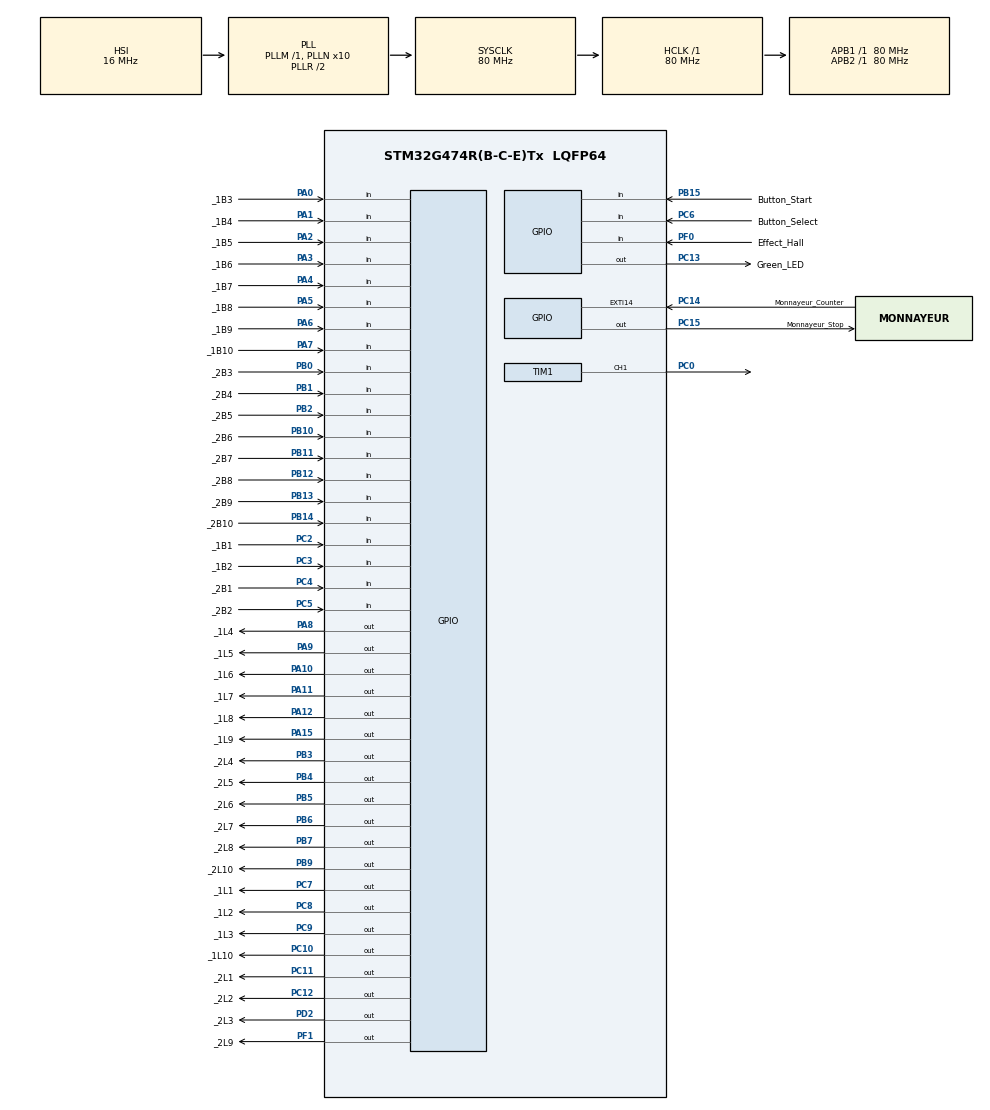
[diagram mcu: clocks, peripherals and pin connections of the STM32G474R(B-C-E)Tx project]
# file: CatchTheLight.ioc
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Dma.Request0=TIM1_CH1
Dma.TIM1_CH1.0.Direction=DMA_MEMORY_TO_PERIPH
Dma.TIM1_CH1.0.EventEnable=DISABLE
Dma.TIM1_CH1.0.Instance=DMA1_Channel1
Dma.TIM1_CH1.0.MemDataAlignment=DMA_MDATAALIGN_HALFWORD
Dma.TIM1_CH1.0.MemInc=DMA_MINC_ENABLE
Dma.TIM1_CH1.0.Mode=DMA_NORMAL
Dma.TIM1_CH1.0.PeriphDataAlignment=DMA_PDATAALIGN_HALFWORD
Dma.TIM1_CH1.0.PeriphInc=DMA_PINC_DISABLE
Dma.TIM1_CH1.0.Polarity=HAL_DMAMUX_REQ_GEN_RISING
Dma.TIM1_CH1.0.Priority=DMA_PRIORITY_MEDIUM
Dma.TIM1_CH1.0.RequestNumber=1
Dma.TIM1_CH1.0.SignalID=NONE
Dma.TIM1_CH1.0.SyncEnable=DISABLE
Dma.TIM1_CH1.0.SyncPolarity=HAL_DMAMUX_SYNC_NO_EVENT
Dma.TIM1_CH1.0.SyncRequestNumber=1
Dma.TIM1_CH1.0.SyncSignalID=NONE
Mcu.Family=STM32G4
Mcu.Name=STM32G474R(B-C-E)Tx
Mcu.Package=LQFP64
NVIC.DMA1_Channel1_IRQn=true\:0\:0\:false\:false\:true\:false\:true\:true
NVIC.PriorityGroup=NVIC_PRIORITYGROUP_4
PA0.GPIO_Label=_1B3
PA0.Signal=GPIO_Input
PA1.GPIO_Label=_1B4
PA1.Signal=GPIO_Input
PA10.GPIO_Label=_1L6
PA10.Signal=GPIO_Output
PA11.GPIO_Label=_1L7
PA11.Signal=GPIO_Output
PA12.GPIO_Label=_1L8
PA12.Signal=GPIO_Output
PA13.Mode=Serial_Wire
PA13.Signal=SYS_JTMS-SWDIO
PA14.Mode=Serial_Wire
PA14.Signal=SYS_JTCK-SWCLK
PA15.GPIO_Label=_1L9
PA15.Signal=GPIO_Output
PA2.GPIO_Label=_1B5
PA2.Signal=GPIO_Input
PA3.GPIO_Label=_1B6
PA3.Signal=GPIO_Input
PA4.GPIO_Label=_1B7
PA4.Signal=GPIO_Input
PA5.GPIO_Label=_1B8
PA5.Signal=GPIO_Input
PA6.GPIO_Label=_1B9
PA6.Signal=GPIO_Input
PA7.GPIO_Label=_1B10
PA7.Signal=GPIO_Input
PA8.GPIO_Label=_1L4
PA8.Signal=GPIO_Output
PA9.GPIO_Label=_1L5
PA9.Signal=GPIO_Output
PB0.GPIO_Label=_2B3
PB0.Signal=GPIO_Input
PB1.GPIO_Label=_2B4
PB1.Signal=GPIO_Input
PB10.GPIO_Label=_2B6
PB10.Signal=GPIO_Input
PB11.GPIO_Label=_2B7
PB11.Signal=GPIO_Input
PB12.GPIO_Label=_2B8
PB12.Signal=GPIO_Input
PB13.GPIO_Label=_2B9
PB13.Signal=GPIO_Input
PB14.GPIO_Label=_2B10
PB14.Signal=GPIO_Input
PB15.GPIO_Label=Button_Start
PB15.Signal=GPIO_Input
PB2.GPIO_Label=_2B5
PB2.Signal=GPIO_Input
PB3.GPIO_Label=_2L4
PB3.Signal=GPIO_Output
PB4.GPIO_Label=_2L5
PB4.Signal=GPIO_Output
PB5.GPIO_Label=_2L6
PB5.Signal=GPIO_Output
PB6.GPIO_Label=_2L7
PB6.Signal=GPIO_Output
PB7.GPIO_Label=_2L8
PB7.Signal=GPIO_Output
PB9.GPIO_Label=_2L10
PB9.Signal=GPIO_Output
PC0.Signal=S_TIM1_CH1
PC10.GPIO_Label=_1L10
PC10.Signal=GPIO_Output
PC11.GPIO_Label=_2L1
PC11.Signal=GPIO_Output
PC12.GPIO_Label=_2L2
PC12.Signal=GPIO_Output
PC13.GPIO_Label=Green_LED
PC13.Signal=GPIO_Output
PC14-OSC32_IN.GPIO_Label=Monnayeur_Counter
PC14-OSC32_IN.Signal=GPXTI14
PC15-OSC32_OUT.GPIO_Label=Monnayeur_Stop
PC15-OSC32_OUT.Signal=GPIO_Output
PC2.GPIO_Label=_1B1
PC2.Signal=GPIO_Input
PC3.GPIO_Label=_1B2
PC3.Signal=GPIO_Input
PC4.GPIO_Label=_2B1
PC4.Signal=GPIO_Input
PC5.GPIO_Label=_2B2
PC5.Signal=GPIO_Input
PC6.GPIO_Label=Button_Select
PC6.Signal=GPIO_Input
PC7.GPIO_Label=_1L1
PC7.Signal=GPIO_Output
PC8.GPIO_Label=_1L2
PC8.Signal=GPIO_Output
PC9.GPIO_Label=_1L3
PC9.Signal=GPIO_Output
PD2.GPIO_Label=_2L3
PD2.Signal=GPIO_Output
PF0-OSC_IN.GPIO_Label=Effect_Hall
PF0-OSC_IN.Signal=GPIO_Input
PF1-OSC_OUT.GPIO_Label=_2L9
PF1-OSC_OUT.Signal=GPIO_Output
ProjectManager.HeapSize=0x200
ProjectManager.StackSize=0x400
ProjectManager.TargetToolchain=STM32CubeIDE
RCC.ADC12Freq_Value=80000000
RCC.ADC345Freq_Value=80000000
RCC.AHBFreq_Value=80000000
RCC.APB1Freq_Value=80000000
RCC.APB1TimFreq_Value=80000000
RCC.APB2Freq_Value=80000000
RCC.APB2TimFreq_Value=80000000
RCC.CortexFreq_Value=80000000
RCC.EXTERNAL_CLOCK_VALUE=12288000
RCC.HCLKFreq_Value=80000000
RCC.HSE_VALUE=8000000
RCC.HSI48_VALUE=48000000
RCC.HSI_VALUE=16000000
RCC.LSE_VALUE=32768
RCC.PLLN=10
RCC.SYSCLKFreq_VALUE=80000000
RCC.SYSCLKSource=RCC_SYSCLKSOURCE_PLLCLK
RCC.USBFreq_Value=80000000
RCC.VCOOutputFreq_Value=160000000
SH.S_TIM1_CH1.0=TIM1_CH1,PWM Generation1 CH1
TIM1.Channel-PWM\ Generation1\ CH1=TIM_CHANNEL_1
TIM1.PeriodNoDither=79
VP_SYS_VS_DBSignals.Mode=DisableDeadBatterySignals
VP_TIM1_VS_ClockSourceINT.Mode=Internal
board=custom

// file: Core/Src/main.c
/* USER CODE BEGIN Header */
/**
 ******************************************************************************
 * @file           : main.c
 * @brief          : Main program body
 ******************************************************************************
 * @attention
 *
 * Copyright (c) 2026 STMicroelectronics.
 * All rights reserved.
 *
 * This software is licensed under terms that can be found in the LICENSE file
 * in the root directory of this software component.
 * If no LICENSE file comes with this software, it is provided AS-IS.
 *
 ******************************************************************************
 */
/* USER CODE END Header */
#include "main.h"

/* USER CODE BEGIN Includes */
#include "utils.h"
/* USER CODE END Includes */

TIM_HandleTypeDef htim1;
DMA_HandleTypeDef hdma_tim1_ch1;

void SystemClock_Config(void);
static void MX_GPIO_Init(void);
static void MX_DMA_Init(void);
static void MX_TIM1_Init(void);

int main(void)
{

	/* MCU Configuration--------------------------------------------------------*/

	/* Reset of all peripherals, Initializes the Flash interface and the Systick. */
	HAL_Init();

	/* Configure the system clock */
	SystemClock_Config();

	/* Initialize all configured peripherals */
	MX_GPIO_Init();
	MX_DMA_Init();
	MX_TIM1_Init();
	/* USER CODE BEGIN 2 */

	SETUP();
	//setup();

	/* USER CODE END 2 */

	/* Infinite loop */
	while (1)
	{

		/* USER CODE BEGIN 3 */
		//		HAL_GPIO_WritePin(GPIOB,GPIO_PIN_9,SET);
		//		HAL_Delay(1000);
		//		if (HAL_GPIO_ReadPin(GPIOC,GPIO_PIN_2)==0)
		//		{
		//			HAL_GPIO_WritePin(GPIOC,GPIO_PIN_13,1);
		//		}
		//		HAL_GPIO_WritePin(GPIOC,GPIO_PIN_13,0);
		//		HAL_Delay(1000);
		//		HAL_GPIO_WritePin(GPIOF,GPIO_PIN_1,SET);
		//test_led();
		//blinking_all();
		//if (HAL_GPIO_ReadPin(GPIOB,GPIO_PIN_15)==0){EteindreAll();}
		//EteindreAll();
		//=================================================================
		LOOP();
		//chenillard2();
		//inv_chenillard2();
		//test();
		//loop();
//		zero(1,'b');
//		HAL_Delay(1000);
//		un(1,'b');
//		HAL_Delay(1000);
//		deux(1,'b');
//		HAL_Delay(1000);
//		trois(1,'b');
//		HAL_Delay(1000);
//		quatre(1,'b');
//		HAL_Delay(1000);
//		cinq(1,'b');
//		HAL_Delay(1000);
//		six(1,'b');
//		HAL_Delay(1000);
//		sept(1,'b');
//		HAL_Delay(1000);
//		huit(1,'b');
//		HAL_Delay(1000);
//		neuf(1,'b');
//		HAL_Delay(1000);

	}
	/* USER CODE END 3 */
}

void SystemClock_Config(void)
{
	RCC_OscInitTypeDef RCC_OscInitStruct = {0};
	RCC_ClkInitTypeDef RCC_ClkInitStruct = {0};

	/** Configure the main internal regulator output voltage
	 */
	HAL_PWREx_ControlVoltageScaling(PWR_REGULATOR_VOLTAGE_SCALE1);

	/** Initializes the RCC Oscillators according to the specified parameters
	 * in the RCC_OscInitTypeDef structure.
	 */
	RCC_OscInitStruct.OscillatorType = RCC_OSCILLATORTYPE_HSI;
	RCC_OscInitStruct.HSIState = RCC_HSI_ON;
	RCC_OscInitStruct.HSICalibrationValue = RCC_HSICALIBRATION_DEFAULT;
	RCC_OscInitStruct.PLL.PLLState = RCC_PLL_ON;
	RCC_OscInitStruct.PLL.PLLSource = RCC_PLLSOURCE_HSI;
	RCC_OscInitStruct.PLL.PLLM = RCC_PLLM_DIV1;
	RCC_OscInitStruct.PLL.PLLN = 10;
	RCC_OscInitStruct.PLL.PLLP = RCC_PLLP_DIV2;
	RCC_OscInitStruct.PLL.PLLQ = RCC_PLLQ_DIV2;
	RCC_OscInitStruct.PLL.PLLR = RCC_PLLR_DIV2;
	if (HAL_RCC_OscConfig(&RCC_OscInitStruct) != HAL_OK)
	{
		Error_Handler();
	}

	/** Initializes the CPU, AHB and APB buses clocks
	 */
	RCC_ClkInitStruct.ClockType = RCC_CLOCKTYPE_HCLK|RCC_CLOCKTYPE_SYSCLK
			|RCC_CLOCKTYPE_PCLK1|RCC_CLOCKTYPE_PCLK2;
	RCC_ClkInitStruct.SYSCLKSource = RCC_SYSCLKSOURCE_PLLCLK;
	RCC_ClkInitStruct.AHBCLKDivider = RCC_SYSCLK_DIV1;
	RCC_ClkInitStruct.APB1CLKDivider = RCC_HCLK_DIV1;
	RCC_ClkInitStruct.APB2CLKDivider = RCC_HCLK_DIV1;

	if (HAL_RCC_ClockConfig(&RCC_ClkInitStruct, FLASH_LATENCY_2) != HAL_OK)
	{
		Error_Handler();
	}
}

static void MX_TIM1_Init(void)
{

	TIM_ClockConfigTypeDef sClockSourceConfig = {0};
	TIM_MasterConfigTypeDef sMasterConfig = {0};
	TIM_OC_InitTypeDef sConfigOC = {0};
	TIM_BreakDeadTimeConfigTypeDef sBreakDeadTimeConfig = {0};

	htim1.Instance = TIM1;
	htim1.Init.Prescaler = 0;
	htim1.Init.CounterMode = TIM_COUNTERMODE_UP;
	htim1.Init.Period = 79;
	htim1.Init.ClockDivision = TIM_CLOCKDIVISION_DIV1;
	htim1.Init.RepetitionCounter = 0;
	htim1.Init.AutoReloadPreload = TIM_AUTORELOAD_PRELOAD_DISABLE;
	if (HAL_TIM_Base_Init(&htim1) != HAL_OK)
	{
		Error_Handler();
	}
	sClockSourceConfig.ClockSource = TIM_CLOCKSOURCE_INTERNAL;
	if (HAL_TIM_ConfigClockSource(&htim1, &sClockSourceConfig) != HAL_OK)
	{
		Error_Handler();
	}
	if (HAL_TIM_PWM_Init(&htim1) != HAL_OK)
	{
		Error_Handler();
	}
	sMasterConfig.MasterOutputTrigger = TIM_TRGO_RESET;
	sMasterConfig.MasterOutputTrigger2 = TIM_TRGO2_RESET;
	sMasterConfig.MasterSlaveMode = TIM_MASTERSLAVEMODE_DISABLE;
	if (HAL_TIMEx_MasterConfigSynchronization(&htim1, &sMasterConfig) != HAL_OK)
	{
		Error_Handler();
	}
	sConfigOC.OCMode = TIM_OCMODE_PWM1;
	sConfigOC.Pulse = 0;
	sConfigOC.OCPolarity = TIM_OCPOLARITY_HIGH;
	sConfigOC.OCNPolarity = TIM_OCNPOLARITY_HIGH;
	sConfigOC.OCFastMode = TIM_OCFAST_DISABLE;
	sConfigOC.OCIdleState = TIM_OCIDLESTATE_RESET;
	sConfigOC.OCNIdleState = TIM_OCNIDLESTATE_RESET;
	if (HAL_TIM_PWM_ConfigChannel(&htim1, &sConfigOC, TIM_CHANNEL_1) != HAL_OK)
	{
		Error_Handler();
	}
	sBreakDeadTimeConfig.OffStateRunMode = TIM_OSSR_DISABLE;
	sBreakDeadTimeConfig.OffStateIDLEMode = TIM_OSSI_DISABLE;
	sBreakDeadTimeConfig.LockLevel = TIM_LOCKLEVEL_OFF;
	sBreakDeadTimeConfig.DeadTime = 0;
	sBreakDeadTimeConfig.BreakState = TIM_BREAK_DISABLE;
	sBreakDeadTimeConfig.BreakPolarity = TIM_BREAKPOLARITY_HIGH;
	sBreakDeadTimeConfig.BreakFilter = 0;
	sBreakDeadTimeConfig.BreakAFMode = TIM_BREAK_AFMODE_INPUT;
	sBreakDeadTimeConfig.Break2State = TIM_BREAK2_DISABLE;
	sBreakDeadTimeConfig.Break2Polarity = TIM_BREAK2POLARITY_HIGH;
	sBreakDeadTimeConfig.Break2Filter = 0;
	sBreakDeadTimeConfig.Break2AFMode = TIM_BREAK_AFMODE_INPUT;
	sBreakDeadTimeConfig.AutomaticOutput = TIM_AUTOMATICOUTPUT_DISABLE;
	if (HAL_TIMEx_ConfigBreakDeadTime(&htim1, &sBreakDeadTimeConfig) != HAL_OK)
	{
		Error_Handler();
	}
	HAL_TIM_MspPostInit(&htim1);

}

static void MX_DMA_Init(void)
{

	/* DMA controller clock enable */
	__HAL_RCC_DMAMUX1_CLK_ENABLE();
	__HAL_RCC_DMA1_CLK_ENABLE();

	/* DMA interrupt init */
	/* DMA1_Channel1_IRQn interrupt configuration */
	HAL_NVIC_SetPriority(DMA1_Channel1_IRQn, 0, 0);
	HAL_NVIC_EnableIRQ(DMA1_Channel1_IRQn);

}

static void MX_GPIO_Init(void)
{
	GPIO_InitTypeDef GPIO_InitStruct = {0};

	/* GPIO Ports Clock Enable */
	__HAL_RCC_GPIOC_CLK_ENABLE();
	__HAL_RCC_GPIOF_CLK_ENABLE();
	__HAL_RCC_GPIOA_CLK_ENABLE();
	__HAL_RCC_GPIOB_CLK_ENABLE();
	__HAL_RCC_GPIOD_CLK_ENABLE();

	/*Configure GPIO pin Output Level */
	HAL_GPIO_WritePin(GPIOC, Green_LED_Pin|Monnayeur_Stop_Pin|_1L1_Pin|_1L2_Pin
			|_1L3_Pin|_1L10_Pin|_2L1_Pin|_2L2_Pin, GPIO_PIN_RESET);

	/*Configure GPIO pin Output Level */
	HAL_GPIO_WritePin(_2L9_GPIO_Port, _2L9_Pin, GPIO_PIN_RESET);

	/*Configure GPIO pin Output Level */
	HAL_GPIO_WritePin(GPIOA, _1L4_Pin|_1L5_Pin|_1L6_Pin|_1L7_Pin
			|_1L8_Pin|_1L9_Pin, GPIO_PIN_RESET);

	/*Configure GPIO pin Output Level */
	HAL_GPIO_WritePin(_2L3_GPIO_Port, _2L3_Pin, GPIO_PIN_RESET);

	/*Configure GPIO pin Output Level */
	HAL_GPIO_WritePin(GPIOB, _2L4_Pin|_2L5_Pin|_2L6_Pin|_2L7_Pin
			|_2L8_Pin|_2L10_Pin, GPIO_PIN_RESET);

	/*Configure GPIO pins : Green_LED_Pin Monnayeur_Stop_Pin _1L1_Pin _1L2_Pin
                           _1L3_Pin _1L10_Pin _2L1_Pin _2L2_Pin */
	GPIO_InitStruct.Pin = Green_LED_Pin|Monnayeur_Stop_Pin|_1L1_Pin|_1L2_Pin
			|_1L3_Pin|_1L10_Pin|_2L1_Pin|_2L2_Pin;
	GPIO_InitStruct.Mode = GPIO_MODE_OUTPUT_PP;
	GPIO_InitStruct.Pull = GPIO_NOPULL;
	GPIO_InitStruct.Speed = GPIO_SPEED_FREQ_LOW;
	HAL_GPIO_Init(GPIOC, &GPIO_InitStruct);

	/*Configure GPIO pin : Monnayeur_Counter_Pin */
	GPIO_InitStruct.Pin = Monnayeur_Counter_Pin;
	GPIO_InitStruct.Mode = GPIO_MODE_IT_RISING;
	GPIO_InitStruct.Pull = GPIO_NOPULL;
	HAL_GPIO_Init(Monnayeur_Counter_GPIO_Port, &GPIO_InitStruct);

	/*Configure GPIO pin : Effect_Hall_Pin */
	GPIO_InitStruct.Pin = Effect_Hall_Pin;
	GPIO_InitStruct.Mode = GPIO_MODE_INPUT;
	GPIO_InitStruct.Pull = GPIO_NOPULL;
	HAL_GPIO_Init(Effect_Hall_GPIO_Port, &GPIO_InitStruct);

	/*Configure GPIO pin : _2L9_Pin */
	GPIO_InitStruct.Pin = _2L9_Pin;
	GPIO_InitStruct.Mode = GPIO_MODE_OUTPUT_PP;
	GPIO_InitStruct.Pull = GPIO_NOPULL;
	GPIO_InitStruct.Speed = GPIO_SPEED_FREQ_LOW;
	HAL_GPIO_Init(_2L9_GPIO_Port, &GPIO_InitStruct);

	/*Configure GPIO pins : _1B1_Pin _1B2_Pin _2B1_Pin _2B2_Pin
                           Button_Select_Pin */
	GPIO_InitStruct.Pin = _1B1_Pin|_1B2_Pin|_2B1_Pin|_2B2_Pin
			|Button_Select_Pin;
	GPIO_InitStruct.Mode = GPIO_MODE_INPUT;
	GPIO_InitStruct.Pull = GPIO_NOPULL;
	HAL_GPIO_Init(GPIOC, &GPIO_InitStruct);

	/*Configure GPIO pins : _1B3_Pin _1B4_Pin _1B5_Pin _1B6_Pin
                           _1B7_Pin _1B8_Pin _1B9_Pin _1B10_Pin */
	GPIO_InitStruct.Pin = _1B3_Pin|_1B4_Pin|_1B5_Pin|_1B6_Pin
			|_1B7_Pin|_1B8_Pin|_1B9_Pin|_1B10_Pin;
	GPIO_InitStruct.Mode = GPIO_MODE_INPUT;
	GPIO_InitStruct.Pull = GPIO_NOPULL;
	HAL_GPIO_Init(GPIOA, &GPIO_InitStruct);

	/*Configure GPIO pins : _2B3_Pin _2B4_Pin _2B5_Pin _2B6_Pin
                           _2B7_Pin _2B8_Pin _2B9_Pin _2B10_Pin
                           Button_Start_Pin */
	GPIO_InitStruct.Pin = _2B3_Pin|_2B4_Pin|_2B5_Pin|_2B6_Pin
			|_2B7_Pin|_2B8_Pin|_2B9_Pin|_2B10_Pin
			|Button_Start_Pin;
	GPIO_InitStruct.Mode = GPIO_MODE_INPUT;
	GPIO_InitStruct.Pull = GPIO_NOPULL;
	HAL_GPIO_Init(GPIOB, &GPIO_InitStruct);

	/*Configure GPIO pins : _1L4_Pin _1L5_Pin _1L6_Pin _1L7_Pin
                           _1L8_Pin _1L9_Pin */
	GPIO_InitStruct.Pin = _1L4_Pin|_1L5_Pin|_1L6_Pin|_1L7_Pin
			|_1L8_Pin|_1L9_Pin;
	GPIO_InitStruct.Mode = GPIO_MODE_OUTPUT_PP;
	GPIO_InitStruct.Pull = GPIO_NOPULL;
	GPIO_InitStruct.Speed = GPIO_SPEED_FREQ_LOW;
	HAL_GPIO_Init(GPIOA, &GPIO_InitStruct);

	/*Configure GPIO pin : _2L3_Pin */
	GPIO_InitStruct.Pin = _2L3_Pin;
	GPIO_InitStruct.Mode = GPIO_MODE_OUTPUT_PP;
	GPIO_InitStruct.Pull = GPIO_NOPULL;
	GPIO_InitStruct.Speed = GPIO_SPEED_FREQ_LOW;
	HAL_GPIO_Init(_2L3_GPIO_Port, &GPIO_InitStruct);

	/*Configure GPIO pins : _2L4_Pin _2L5_Pin _2L6_Pin _2L7_Pin
                           _2L8_Pin _2L10_Pin */
	GPIO_InitStruct.Pin = _2L4_Pin|_2L5_Pin|_2L6_Pin|_2L7_Pin
			|_2L8_Pin|_2L10_Pin;
	GPIO_InitStruct.Mode = GPIO_MODE_OUTPUT_PP;
	GPIO_InitStruct.Pull = GPIO_NOPULL;
	GPIO_InitStruct.Speed = GPIO_SPEED_FREQ_LOW;
	HAL_GPIO_Init(GPIOB, &GPIO_InitStruct);

}

void Error_Handler(void)
{
	__disable_irq();
	while (1)
	{
	}
}
